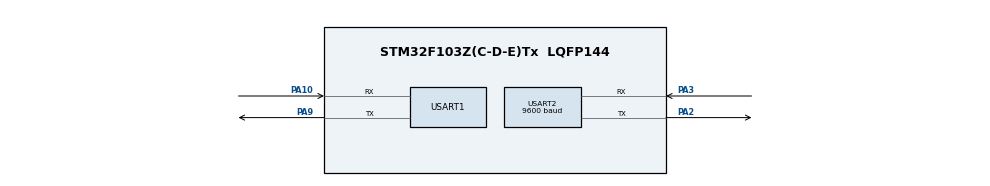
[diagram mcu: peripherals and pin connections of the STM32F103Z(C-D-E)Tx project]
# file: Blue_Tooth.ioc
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Mcu.Family=STM32F1
Mcu.Name=STM32F103Z(C-D-E)Tx
Mcu.Package=LQFP144
NVIC.PriorityGroup=NVIC_PRIORITYGROUP_4
OSC_IN.Mode=HSE-External-Oscillator
OSC_IN.Signal=RCC_OSC_IN
OSC_OUT.Mode=HSE-External-Oscillator
OSC_OUT.Signal=RCC_OSC_OUT
PA10.Mode=Asynchronous
PA10.Signal=USART1_RX
PA13.Mode=Serial_Wire
PA13.Signal=SYS_JTMS-SWDIO
PA14.Mode=Serial_Wire
PA14.Signal=SYS_JTCK-SWCLK
PA2.Mode=Asynchronous
PA2.Signal=USART2_TX
PA3.Mode=Asynchronous
PA3.Signal=USART2_RX
PA9.Mode=Asynchronous
PA9.Signal=USART1_TX
ProjectManager.HeapSize=0x200
ProjectManager.StackSize=0x400
ProjectManager.TargetToolchain=MDK-ARM V5.32
RCC.APB1Freq_Value=8000000
RCC.APB2Freq_Value=8000000
USART1.VirtualMode=VM_ASYNC
USART2.BaudRate=9600
USART2.VirtualMode=VM_ASYNC
board=custom

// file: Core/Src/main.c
/* USER CODE BEGIN Header */
/**
  ******************************************************************************
  * @file           : main.c
  * @brief          : Main program body
  ******************************************************************************
  * @attention
  *
  * Copyright (c) 2023 STMicroelectronics.
  * All rights reserved.
  *
  * This software is licensed under terms that can be found in the LICENSE file
  * in the root directory of this software component.
  * If no LICENSE file comes with this software, it is provided AS-IS.
  *
  ******************************************************************************
  */
/* USER CODE END Header */
#include "main.h"
#include "usart.h"
#include "gpio.h"

/* USER CODE BEGIN Includes */
#include <stdio.h>
/* USER CODE END Includes */

void SystemClock_Config(void);
/* USER CODE BEGIN PFP */
uint8_t com_data = 0;
int RX[4] = {0,0,0,0};
/* USER CODE END PFP */

int main(void)
{

  /* MCU Configuration--------------------------------------------------------*/

  /* Reset of all peripherals, Initializes the Flash interface and the Systick. */
  HAL_Init();

  /* Configure the system clock */
  SystemClock_Config();

  /* Initialize all configured peripherals */
  MX_GPIO_Init();
  MX_USART1_UART_Init();
  MX_USART2_UART_Init();
  /* USER CODE BEGIN 2 */
		HAL_UART_Receive_IT(&huart2,&com_data,1);//启动接收函数
  /* USER CODE END 2 */

  /* Infinite loop */
  while (1)
  {
		printf("%d, %d, %d, %d\n", RX[0], RX[1], RX[2], RX[3]);
  }
}

void SystemClock_Config(void)
{
  RCC_OscInitTypeDef RCC_OscInitStruct = {0};
  RCC_ClkInitTypeDef RCC_ClkInitStruct = {0};

  /** Initializes the RCC Oscillators according to the specified parameters
  * in the RCC_OscInitTypeDef structure.
  */
  RCC_OscInitStruct.OscillatorType = RCC_OSCILLATORTYPE_HSI;
  RCC_OscInitStruct.HSIState = RCC_HSI_ON;
  RCC_OscInitStruct.HSICalibrationValue = RCC_HSICALIBRATION_DEFAULT;
  RCC_OscInitStruct.PLL.PLLState = RCC_PLL_NONE;
  if (HAL_RCC_OscConfig(&RCC_OscInitStruct) != HAL_OK)
  {
    Error_Handler();
  }

  /** Initializes the CPU, AHB and APB buses clocks
  */
  RCC_ClkInitStruct.ClockType = RCC_CLOCKTYPE_HCLK|RCC_CLOCKTYPE_SYSCLK
                              |RCC_CLOCKTYPE_PCLK1|RCC_CLOCKTYPE_PCLK2;
  RCC_ClkInitStruct.SYSCLKSource = RCC_SYSCLKSOURCE_HSI;
  RCC_ClkInitStruct.AHBCLKDivider = RCC_SYSCLK_DIV1;
  RCC_ClkInitStruct.APB1CLKDivider = RCC_HCLK_DIV1;
  RCC_ClkInitStruct.APB2CLKDivider = RCC_HCLK_DIV1;

  if (HAL_RCC_ClockConfig(&RCC_ClkInitStruct, FLASH_LATENCY_0) != HAL_OK)
  {
    Error_Handler();
  }
}

///重定向c库函数printf到串口DEBUG_USART，重定向后可使用printf函数
void HAL_UART_RxCpltCallback(UART_HandleTypeDef *huart)
{
  if(huart->Instance == USART3)
  {
    uint8_t i;
		static uint8_t RxCounter1=0;//计数
		static uint16_t RxBuffer1[10]={0};
		static uint8_t RxState = 0;
		static uint8_t RxFlag1 = 0;

		if(RxState==0&&com_data==0x2C)  //0x2c帧头
		{

			RxState=1;
			RxBuffer1[RxCounter1++]=com_data;
		}

		else if(RxState==1)
		{

			RxBuffer1[RxCounter1++]=com_data;
			if(RxCounter1>=10||com_data == 0x5B)       //RxBuffer1接受满了,接收数据结束
			{
				RxState=2;
				RxFlag1=1;

				 //正常情况下,运行到这RxCounter1 == 7？  7-5 = 2    openmv发送过来的一个数据包有8个
				RX[0] =          RxBuffer1[RxCounter1-5];
				RX[1] =          RxBuffer1[RxCounter1-4];     //-1是左， 1是右，0表示还没有识别到任何数字
				RX[2] =  		RxBuffer1[RxCounter1-3];
				RX[3] =      RxBuffer1[RxCounter1-2];

				//RxCounter1-1是帧尾
			}
		}

		else if(RxState==3)		//检测是否接受到结束标志
		{
				if(RxBuffer1[RxCounter1-1] == 0x5B)
				{

							RxFlag1 = 0;
							RxCounter1 = 0;
							RxState = 0;

				}
				else   //接收错误
				{
							RxState = 0;
							RxCounter1=0;
							for(i=0;i<10;i++)
							{
									RxBuffer1[i]=0x00;      //将存放数据数组清零
							}
				}
		}

		else   //接收异常
		{
				RxState = 0;
				RxCounter1=0;
				for(i=0;i<10;i++)
				{
						RxBuffer1[i]=0x00;      //将存放数据数组清零
				}
		}
		HAL_UART_Receive_IT(&huart2,&com_data,1);//启动接收函数
  }
}

int fputc(int ch, FILE *f)
{
	/* 发送一个字节数据到串口DEBUG_USART */
	HAL_UART_Transmit(&huart1, (uint8_t *)&ch, 1, 1000);

	return (ch);
}

///重定向c库函数scanf到串口DEBUG_USART，重写向后可使用scanf、getchar等函数
int fgetc(FILE *f)
{
	int ch;
	HAL_UART_Receive(&huart1, (uint8_t *)&ch, 1, 1000);
	return (ch);
}
/* USER CODE END 4 */

void Error_Handler(void)
{
  __disable_irq();
  while (1)
  {
  }
}
